# STM32F042x6 register map
File version: 1.0
Registers are 32-bit, read-write, reset 0x0 unless marked. A register's access mark holds for its fields unless they carry their own. Offsets are from the block's base; [hi:lo] are bit positions; lines under a group give offsets from that group; {n}, {i} and the like mark numbered series.

## ADC1 — Analog to Digital Converter
Base 0x40012400
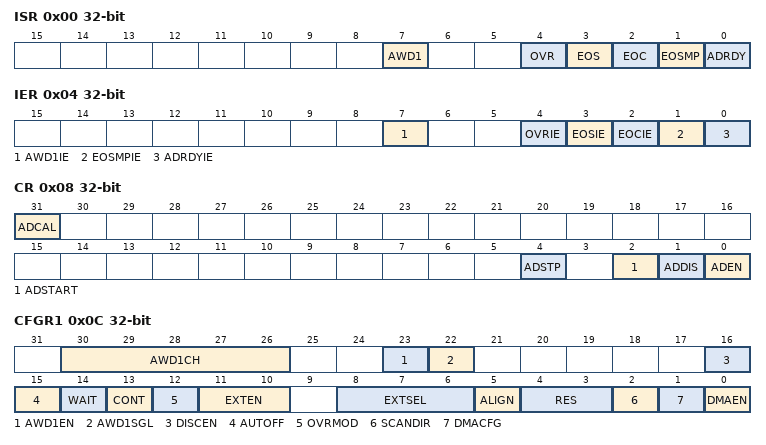
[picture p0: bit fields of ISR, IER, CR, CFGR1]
0x00 ISR — ADC interrupt and status register
  [7] AWD1 — ADC analog watchdog 1 flag
  [4] OVR — ADC group regular overrun flag
  [3] EOS — ADC group regular end of sequence conversions flag
  [2] EOC — ADC group regular end of unitary conversion flag
  [1] EOSMP — ADC group regular end of sampling flag
  [0] ADRDY — ADC ready flag
0x04 IER — ADC interrupt enable register
  [7] AWD1IE — ADC analog watchdog 1 interrupt
  [4] OVRIE — ADC group regular overrun interrupt
  [3] EOSIE — ADC group regular end of sequence conversions interrupt
  [2] EOCIE — ADC group regular end of unitary conversion interrupt
  [1] EOSMPIE — ADC group regular end of sampling interrupt
  [0] ADRDYIE — ADC ready interrupt
0x08 CR — ADC control register
  [31] ADCAL — ADC calibration
  [4] ADSTP — ADC group regular conversion stop
  [2] ADSTART — ADC group regular conversion start
  [1] ADDIS — ADC disable
  [0] ADEN — ADC enable
0x0C CFGR1 — ADC configuration register 1
  [30:26] AWD1CH — ADC analog watchdog 1 monitored channel selection
  [23] AWD1EN — ADC analog watchdog 1 enable on scope ADC group regular
  [22] AWD1SGL — ADC analog watchdog 1 monitoring a single channel or all channels
  [16] DISCEN — ADC group regular sequencer discontinuous mode
    0=DISABLE (ADC group regular sequencer discontinuous mode disable); 1=DISCONT_1RANK (ADC group regular sequencer discontinuous mode enable with sequence interruption every rank)
  [15] AUTOFF — ADC low power auto power off
  [14] WAIT — ADC low power auto wait
  [13] CONT — ADC group regular continuous conversion mode
    0=SINGLE (ADC conversions are performed in single mode: one conversion per trigger); 1=CONTINUOUS (ADC conversions are performed in continuous mode: after the first trigger, following conversions launched successively automatically)
  [12] OVRMOD — ADC group regular overrun configuration
    0=PRESERVED (ADC group regular behavior in case of overrun: data preserved); 1=OVERWRITTEN (ADC group regular behavior in case of overrun: data overwritten)
  [11:10] EXTEN — ADC group regular external trigger polarity
    1=RISING (ADC group regular conversion trigger polarity set to rising edge); 2=FALLING (ADC group regular conversion trigger polarity set to falling edge); 3=RISINGFALLING (ADC group regular conversion trigger polarity set to both rising and falling edges)
  [8:6] EXTSEL — ADC group regular external trigger source
  [5] ALIGN — ADC data alignment
    0=RIGHT (ADC conversion data alignment: right aligned (alignment on data register LSB bit 0)); 1=LEFT (ADC conversion data alignment: left aligned (alignment on data register MSB bit 15))
  [4:3] RES — ADC data resolution
    0=RESOLUTION_12B (ADC resolution 12 bits); 1=RESOLUTION_10B (ADC resolution 10 bits); 2=RESOLUTION_8B (ADC resolution 8 bits); 3=RESOLUTION_6B (ADC resolution 6 bits)
  [2] SCANDIR — ADC group regular sequencer scan direction
    0=FORWARD (ADC group regular sequencer scan direction forward: from lowest channel number to highest channel number (scan of all ranks, ADC conversion of ranks with channels enabled in sequencer). On some other STM32 families, this setting is not available and the default scan direction is forward.); 1=BACKWARD (ADC group regular sequencer scan direction backward: from highest channel number to lowest channel number (scan of all ranks, ADC conversion of ranks with channels enabled in sequencer))
  [1] DMACFG — ADC DMA transfer configuration
  [0] DMAEN — ADC DMA transfer enable
0x10 CFGR2 — ADC configuration register 2
  [31:30] CKMODE — ADC clock source and prescaler (prescaler only for clock source synchronous)
    2=SYNC_PCLK_DIV4 (ADC synchronous clock derived from AHB clock divided by 4); 1=SYNC_PCLK_DIV2 (ADC synchronous clock derived from AHB clock divided by 2); 0=ASYNC (ADC asynchronous clock. On this STM32 series, asynchronous clock has no prescaler.)
0x14 SMPR — ADC sampling time register
  [2:0] SMP — ADC group of channels sampling time 2
    0=SAMPLINGTIME_1CYCLE_5 (Sampling time 1.5 ADC clock cycle); 1=SAMPLINGTIME_7CYCLES_5 (Sampling time 7.5 ADC clock cycles); 2=SAMPLINGTIME_13CYCLES_5 (Sampling time 13.5 ADC clock cycles); 3=SAMPLINGTIME_28CYCLES_5 (Sampling time 28.5 ADC clock cycles); 4=SAMPLINGTIME_41CYCLES_5 (Sampling time 41.5 ADC clock cycles); 5=SAMPLINGTIME_55CYCLES_5 (Sampling time 55.5 ADC clock cycles); 6=SAMPLINGTIME_71CYCLES_5 (Sampling time 71.5 ADC clock cycles); 7=SAMPLINGTIME_239CYCLES_5 (Sampling time 239.5 ADC clock cycles)
0x20 TR — ADC analog watchdog 1 threshold register
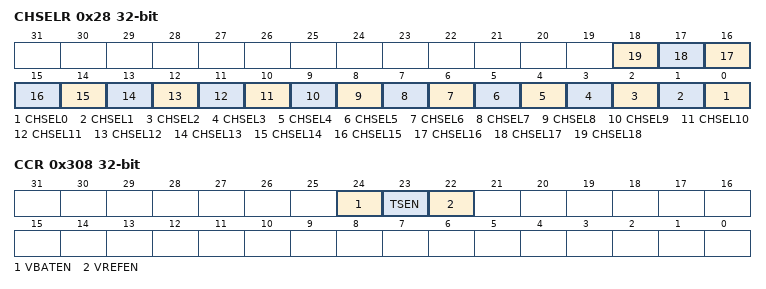
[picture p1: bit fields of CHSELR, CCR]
0x28 CHSELR — ADC group regular sequencer register
  [n] CHSEL{n} (n=0..18) — ADC group regular sequencer channel {n}, available when ADC_CFGR1_CHSELRMOD is reset
0x40 DR — ADC group regular data register
  [15:0] DATA — ADC group regular conversion data
0x308 CCR — ADC common configuration register
  [24] VBATEN — ADC internal path to battery voltage enable
  [23] TSEN — ADC internal path to temperature sensor enable
  [22] VREFEN — ADC internal path to VrefInt enable
